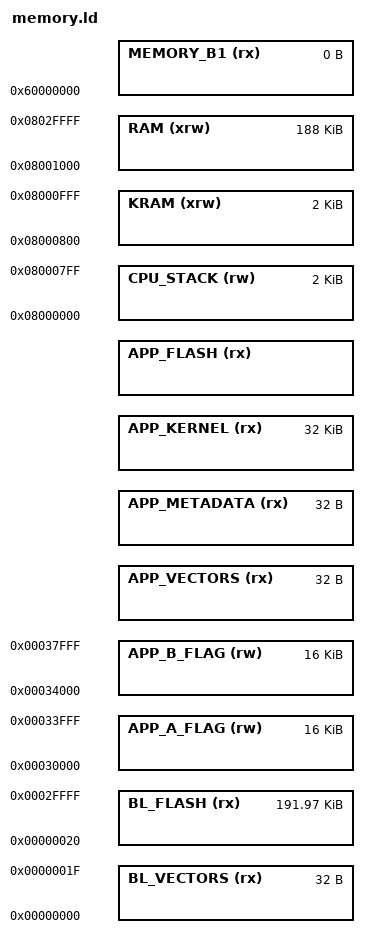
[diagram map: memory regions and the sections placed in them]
MEMORY
{
  BL_VECTORS(rx)      : ORIGIN = 0x00000000, LENGTH = 0x00000020
  BL_FLASH  (rx)      : ORIGIN = 0x00000020, LENGTH = (0x00030000 - 0x00000020)
  APP_A_FLAG (rw)     : ORIGIN = 0x00030000, LENGTH = 0x00004000
  APP_B_FLAG (rw)     : ORIGIN = 0x00034000, LENGTH = 0x00004000
  APP_VECTORS(rx)     : ORIGIN = CUSTOM_START_ADDRESS + APP_ADDRESS_OFFSET, LENGTH = 0x00000020
  APP_METADATA (rx)   : ORIGIN = CUSTOM_START_ADDRESS + APP_ADDRESS_OFFSET + 0x00000020, LENGTH = 0x00000020
  APP_KERNEL (rx)     : ORIGIN = CUSTOM_START_ADDRESS + APP_ADDRESS_OFFSET + 0x00000040, LENGTH = 0x00008000
  APP_FLASH  (rx)     : ORIGIN = CUSTOM_START_ADDRESS + APP_ADDRESS_OFFSET + 0x00008040, LENGTH = (APP_SIZE - 0x00008040)
  CPU_STACK (rw)      : ORIGIN = 0x08000000, LENGTH = 0x00000800 /* Stack is configured in sys_core.asm */
  KRAM (xrw)          : ORIGIN = 0x08000800, LENGTH = 0x00000800
  RAM (xrw)           : ORIGIN = (0x08000800 + 0x00000800), LENGTH = (0x0002f800 - 0x00000800)
  MEMORY_B1 (rx)      : ORIGIN = 0x60000000, LENGTH = 0K
}
